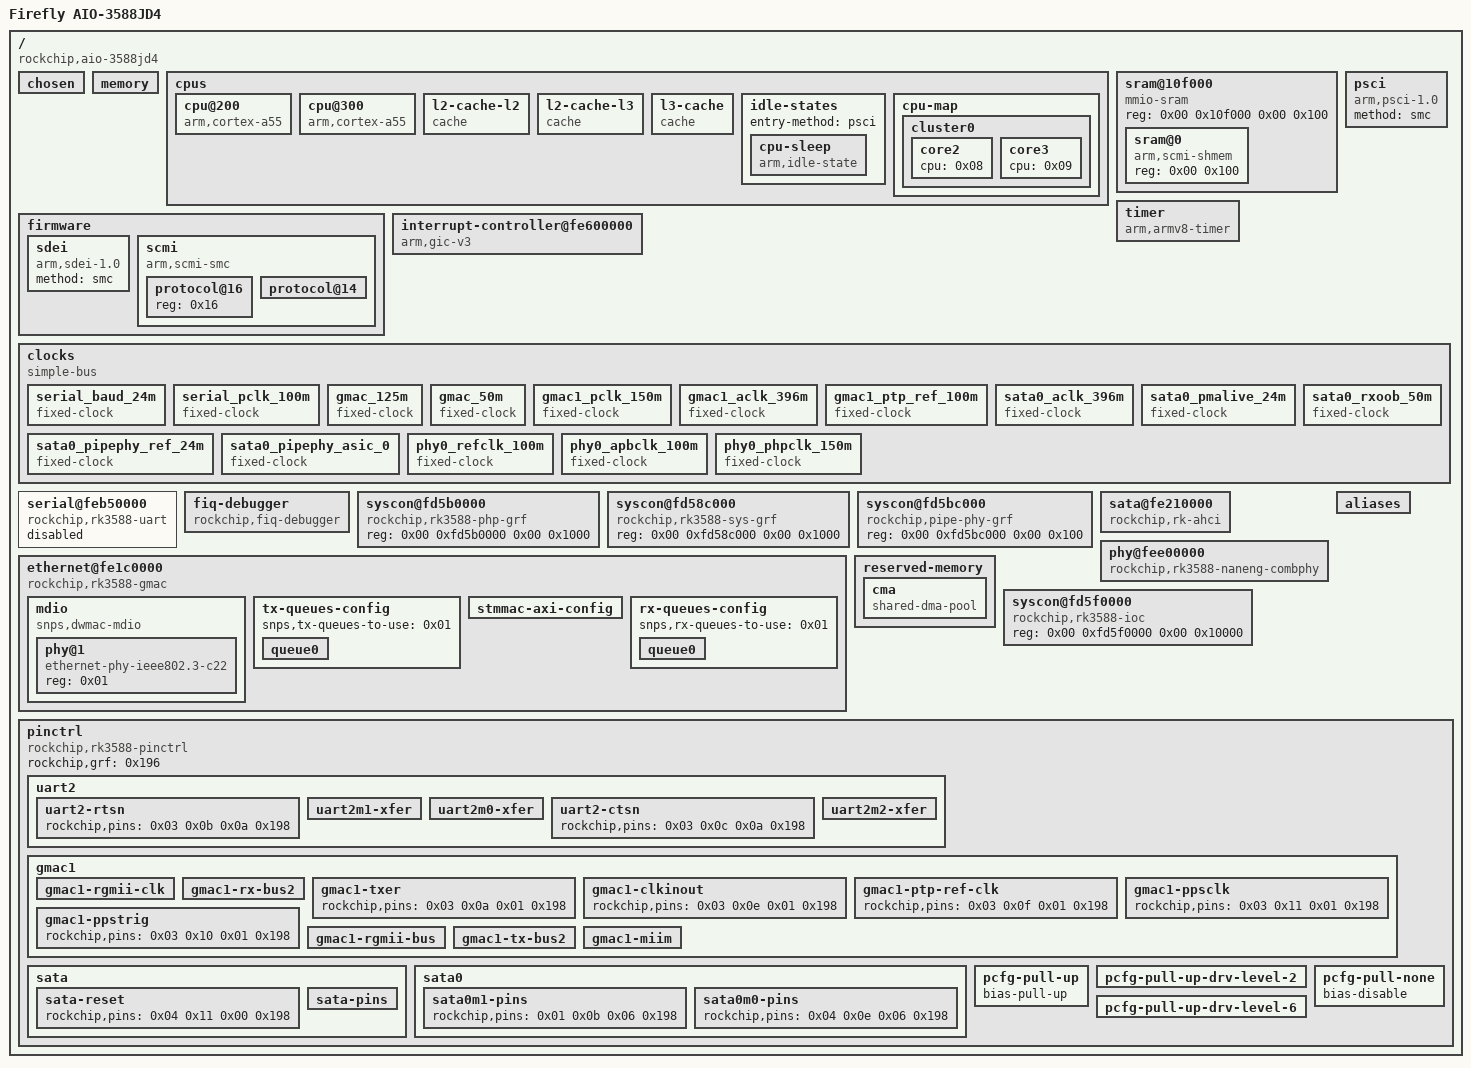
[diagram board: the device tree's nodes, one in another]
/dts-v1/;

/ {
	#address-cells = <0x02>;
	model = "Firefly AIO-3588JD4";
	serial-number = "a0deeea630de3975";
	#size-cells = <0x02>;
	interrupt-parent = <0x01>;
	compatible = "rockchip,aio-3588jd4\0rockchip,rk3588";

	chosen {
		linux,initrd-start = <0x01 0x0a200000>;
		linux,initrd-end = <0x01 0xaac8000>;
		bootargs = "rw earlycon=uart8250,mmio32,0xfeb50000 console=ttyFIQ0 irqchip.gicv3_pseudo_nmi=0 root=/dev/sda1";
		phandle = <0x48d>;
	};

	// DTB memory region: { address: 0xe000_0000, size: 0x1000_0000 } 256M
	// DTB memory region: { address: 0x1_0000_0000, size: 0xe000_0000 } 3.7G


	memory {
		device_type = "memory";
		reg = <0x00 0xe0000000 0x00 0x10000000 0x01 0x00000000 0x00 0xe0000000>;
	};

	cpus {
		#address-cells = <0x01>;
		#size-cells = <0x00>;

		cpu@200 {
			device_type = "cpu";
			compatible = "arm,cortex-a55";
			reg = <0x200>;
			enable-method = "psci";
			capacity-dmips-mhz = <0x212>;
			clocks = <0x0e 0x00>;
			operating-points-v2 = <0x0f>;
			cpu-idle-states = <0x10>;
			i-cache-size = <0x8000>;
			i-cache-line-size = <0x40>;
			i-cache-sets = <0x80>;
			d-cache-size = <0x8000>;
			d-cache-line-size = <0x40>;
			d-cache-sets = <0x80>;
			next-level-cache = <0x14>;
			phandle = <0x08>;
		};

		cpu@300 {
			device_type = "cpu";
			compatible = "arm,cortex-a55";
			reg = <0x300>;
			enable-method = "psci";
			capacity-dmips-mhz = <0x212>;
			clocks = <0x0e 0x00>;
			operating-points-v2 = <0x0f>;
			cpu-idle-states = <0x10>;
			i-cache-size = <0x8000>;
			i-cache-line-size = <0x40>;
			i-cache-sets = <0x80>;
			d-cache-size = <0x8000>;
			d-cache-line-size = <0x40>;
			d-cache-sets = <0x80>;
			next-level-cache = <0x15>;
			phandle = <0x09>;
		};

		l2-cache-l2 {
			compatible = "cache";
			cache-size = <0x20000>;
			cache-line-size = <0x40>;
			cache-sets = <0x200>;
			next-level-cache = <0x1e>;
			phandle = <0x14>;
		};

		l2-cache-l3 {
			compatible = "cache";
			cache-size = <0x20000>;
			cache-line-size = <0x40>;
			cache-sets = <0x200>;
			next-level-cache = <0x1e>;
			phandle = <0x15>;
		};

		l3-cache {
			compatible = "cache";
			cache-size = <0x300000>;
			cache-sets = <0x1000>;
			cache-line-size = <0x40>;
			phandle = <0x1e>;
		};

		idle-states {
			entry-method = "psci";

			cpu-sleep {
				compatible = "arm,idle-state";
				entry-latency-us = <0x64>;
				exit-latency-us = <0x78>;
				min-residency-us = <0x3e8>;
				local-timer-stop;
				arm,psci-suspend-param = <0x10000>;
				phandle = <0x10>;
			};
		};

		cpu-map {
			cluster0 {
				core2 {
					cpu = <0x08>;
				};

				core3 {
					cpu = <0x09>;
				};
			};
		};
	};

	sram@10f000 {
		#address-cells = <0x01>;
		#size-cells = <0x01>;
		compatible = "mmio-sram";
		ranges = <0x00 0x00 0x10f000 0x100>;
		reg = <0x00 0x10f000 0x00 0x100>;

		sram@0 {
			compatible = "arm,scmi-shmem";
			reg = <0x00 0x100>;
			phandle = <0x46>;
		};
	};

	firmware {
		sdei {
			method = "smc";
			compatible = "arm,sdei-1.0";
			phandle = <0x221>;
		};

		scmi {
			shmem = <0x46>;
			#address-cells = <0x01>;
			#size-cells = <0x00>;
			compatible = "arm,scmi-smc";
			phandle = <0x220>;
			arm,smc-id = <0x82000010>;

			protocol@16 {
				#reset-cells = <0x01>;
				reg = <0x16>;
				phandle = <0x11a>;
			};

			protocol@14 {
				assigned-clocks = <0x0e 0x00 0x0e 0x02 0x0e 0x03>;
				assigned-clock-rates = <0x30a32c00 0x30a32c00 0x30a32c00>;
				#clock-cells = <0x01>;
				reg = <0x14>;
				phandle = <0x0e>;
			};
		};
	};

	timer {
		interrupts = <0x01 0x0d 0xf04 0x01 0x0e 0xf04 0x01 0x0b 0xf04 0x01 0x0a 0xf04>;
		compatible = "arm,armv8-timer";
	};

	interrupt-controller@fe600000 {
		#address-cells = <0x02>;
		interrupts = <0x01 0x09 0x04>;
		#size-cells = <0x02>;
		compatible = "arm,gic-v3";
		ranges;
		#interrupt-cells = <0x03>;
		reg = <0x00 0xfe600000 0x00 0x10000 0x00 0xfe6c0000 0x00 0x100000>;
		phandle = <0x01>;
		interrupt-controller;

	};

	psci {
		method = "smc";
		compatible = "arm,psci-1.0";
	};

	// dummy clocks that are configured by VM1
	clocks {
		#address-cells = <0x02>;
		#size-cells = <0x02>;
		compatible = "simple-bus";
		ranges;

		// serial
		serial_baud_24m {
			clock-output-names = "serial_baud_24m";
			compatible = "fixed-clock";
			clock-frequency = <24000000>;
			#clock-cells = <0>;
			phandle = <0xbb>;
		};

		serial_pclk_100m {
			clock-output-names = "serial_pclk_100m";
			compatible = "fixed-clock";
			clock-frequency = <100000000>;
			#clock-cells = <0>;
			phandle = <0xac>;
		};

		// ethernet
		gmac_125m {
			clock-output-names = "gmac_125m";
			compatible = "fixed-clock";
			clock-frequency = <125000000>;
			#clock-cells = <0>;
			phandle = <0x144>;
		};

		gmac_50m {
			clock-output-names = "gmac_50m";
			compatible = "fixed-clock";
			clock-frequency = <50000000>;
			#clock-cells = <0>;
			phandle = <0x145>;
		};

		gmac1_pclk_150m {
			clock-output-names = "gmac1_pclk_150m";
			compatible = "fixed-clock";
			clock-frequency = <150000000>;
			#clock-cells = <0>;
			phandle = <0x168>;
		};

		gmac1_aclk_396m {
			clock-output-names = "gmac1_aclk_396m";
			compatible = "fixed-clock";
			clock-frequency = <396000000>;
			#clock-cells = <0>;
			phandle = <0x16d>;
		};

		gmac1_ptp_ref_100m {
			clock-output-names = "gmac1_ptp_ref_100m";
			compatible = "fixed-clock";
			clock-frequency = <100000000>;
			#clock-cells = <0>;
			phandle = <0x143>;
		};

		sata0_aclk_396m {
			clock-output-names = "sata0_aclk_396m";
			compatible = "fixed-clock";
			clock-frequency = <396000000>;
			#clock-cells = <0>;
			phandle = <0x171>;
		};

		sata0_pmalive_24m {
			clock-output-names = "sata0_pmalive_24m";
			compatible = "fixed-clock";
			clock-frequency = <24000000>;
			#clock-cells = <0>;
			phandle = <0x16e>;
		};

		sata0_rxoob_50m {
			clock-output-names = "sata0_rxoob_50m";
			compatible = "fixed-clock";
			clock-frequency = <50000000>;
			#clock-cells = <0>;
			phandle = <0x174>;
		};

		sata0_pipephy_ref_24m {
			clock-output-names = "sata0_pipephy_ref_24m";
			compatible = "fixed-clock";
			clock-frequency = <24000000>;
			#clock-cells = <0>;
			phandle = <0x163>;
		};

		sata0_pipephy_asic_0 {
			clock-output-names = "sata0_pipephy_asic_0";
			compatible = "fixed-clock";
			clock-frequency = <0>;
			#clock-cells = <0>;
			phandle = <0x17e>;
		};

		phy0_refclk_100m {
			clock-output-names = "phy0_refclk_100m";
			compatible = "fixed-clock";
			clock-frequency = <100000000>;
			#clock-cells = <0>;
			phandle = <0x2bd>;
		};

		phy0_apbclk_100m {
			clock-output-names = "phy0_apbclk_100m";
			compatible = "fixed-clock";
			clock-frequency = <100000000>;
			#clock-cells = <0>;
			phandle = <0x185>;
		};

		phy0_phpclk_150m {
			clock-output-names = "phy0_phpclk_150m";
			compatible = "fixed-clock";
			clock-frequency = <150000000>;
			#clock-cells = <0>;
			phandle = <0x166>;
		};
	};

	serial@feb50000 {
		reg-io-width = <0x04>;
		pinctrl-names = "default";
		pinctrl-0 = <0x161>;
		interrupts = <0x00 0x14d 0x04>;
		// Avoid driver messing with CRU
		clock-names = "baudclk\0apb_pclk";
		clocks = <0xbb 0xac>;
		compatible = "rockchip,rk3588-uart\0snps,dw-apb-uart";
		status = "disabled";
		reg = <0x00 0xfeb50000 0x00 0x100>;
		phandle = <0x2ca>;
		dmas = <0x7c 0x0a 0x7c 0x0b>;
		reg-shift = <0x02>;
	};

	fiq-debugger {
		pinctrl-names = "default";
		rockchip,irq-mode-enable = <0x01>;
		rockchip,baudrate = <0x1c200>;
		pinctrl-0 = <0x1ce>;
		interrupts = <0x00 0x1a7 0x08>;
		rockchip,wake-irq = <0x00>;
		compatible = "rockchip,fiq-debugger";
		status = "okay";
		phandle = <0x490>;
		rockchip,serial-id = <0x02>;
	};

	syscon@fd5b0000 {
		compatible = "rockchip,rk3588-php-grf\0syscon";
		reg = <0x00 0xfd5b0000 0x00 0x1000>;
		phandle = <0x76>;
	};

	syscon@fd58c000 {
		compatible = "rockchip,rk3588-sys-grf\0syscon\0simple-mfd";
		reg = <0x00 0xfd58c000 0x00 0x1000>;
		phandle = <0xc8>;
	};

	syscon@fd5bc000 {
		compatible = "rockchip,pipe-phy-grf\0syscon";
		reg = <0x00 0xfd5bc000 0x00 0x100>;
		phandle = <0x194>;
	};

	sata@fe210000 {
		phy-names = "sata-phy";
		clock-names = "sata\0pmalive\0rxoob\0ref\0asic";
		interrupts = <0x00 0x111 0x04>;
		clocks = <0x171 0x16e 0x174 0x163 0x17e>;
		compatible = "rockchip,rk-ahci\0snps,dwc-ahci";
		status = "okay";
		interrupt-names = "hostc";
		phys = <0x108 0x01>;
		reg = <0x00 0xfe210000 0x00 0x1000>;
		phandle = <0x290>;
		ports-implemented = <0x01>;
	};

	phy@fee00000 {
		rockchip,pipe-grf = <0x76>;
		clock-names = "refclk\0apbclk\0phpclk";
		clocks = <0x2bd 0x185 0x166>;
		#phy-cells = <0x01>;
		compatible = "rockchip,rk3588-naneng-combphy";
		status = "okay";
		rockchip,pipe-phy-grf = <0x194>;
		reg = <0x00 0xfee00000 0x00 0x100>;
		phandle = <0x108>;
		// resets = <0x02 0x20005 0x02 0x4d6>;
		// reset-names = "combphy-apb\0combphy";
	};

	ethernet@fe1c0000 {
		power-domains = <0x60 0x21>;
		pinctrl-names = "default";
		phy-mode = "rgmii-rxid";
		snps,mixed-burst;
		snps,mtl-rx-config = <0x10b>;
		pinctrl-0 = <0x10e 0x10f 0x110 0x111 0x112>;
		clock-names = "stmmaceth\0clk_mac_ref\0pclk_mac\0aclk_mac\0ptp_ref";
		snps,mtl-tx-config = <0x10c>;
		local-mac-address = [a6 50 47 45 20 ee];
		interrupt-names = "macirq\0eth_wake_irq";
		interrupts = <0x00 0xea 0x04 0x00 0xe9 0x04>;
		clocks = <0x144 0x145 0x168 0x16d 0x143>;
		clock_in_out = "output";
		snps,tso;
		compatible = "rockchip,rk3588-gmac\0snps,dwmac-4.20a";
		status = "okay";
		rockchip,grf = <0xc8>;
		// reset-names = "stmmaceth";
		// resets = <0x02 0x20b>;
		// snps,reset-active-low;
		// snps,reset-gpio = <0x10d 0x08 0x01>;
		// snps,reset-delays-us = <0x00 0x4e20 0x186a0>;
		reg = <0x00 0xfe1c0000 0x00 0x10000>;
		rockchip,php_grf = <0x76>;
		phandle = <0x109>;
		phy-handle = <0x113>;
		tx_delay = <0x40>;
		snps,axi-config = <0x10a>;

		mdio {
			#address-cells = <0x01>;
			#size-cells = <0x00>;
			compatible = "snps,dwmac-mdio";
			phandle = <0x28f>;

			phy@1 {
				compatible = "ethernet-phy-ieee802.3-c22";
				reg = <0x01>;
				phandle = <0x113>;
			};
		};

		tx-queues-config {
			phandle = <0x10c>;
			snps,tx-queues-to-use = <0x01>;

			queue0 {
			};
		};

		stmmac-axi-config {
			snps,wr_osr_lmt = <0x04>;
			phandle = <0x10a>;
			snps,blen = <0x00 0x00 0x00 0x00 0x10 0x08 0x04>;
			snps,rd_osr_lmt = <0x08>;
		};

		rx-queues-config {
			snps,rx-queues-to-use = <0x01>;
			phandle = <0x10b>;

			queue0 {
			};
		};
	};

	reserved-memory {
		#address-cells = <0x02>;
		#size-cells = <0x02>;
		ranges;

		cma {
			linux,cma-default;
			compatible = "shared-dma-pool";
			size = <0x00 0x800000>;
			reusable;
		};
	};

	aliases {
		serial2 = "/serial@feb50000";
		ethernet1 = "/ethernet@fe1c0000";
		mmc1 = "/mmc@fe2c0000";
	};

	__symbols__ {
		chosen = "/chosen";
		gic = "/interrupt-controller@fe600000";
		uart2 = "/serial@feb50000";

		scmi_shmem = "/sram@10f000/sram@0";
		scmi = "/firmware/scmi";
		scmi_reset = "/firmware/scmi/protocol@16";
		scmi_clk = "/firmware/scmi/protocol@14";

		gmac1 = "/ethernet@fe1c0000";
		mdio1 = "/ethernet@fe1c0000/mdio";
		rgmii_phy1 = "/ethernet@fe1c0000/mdio/phy@1";
		gmac1_mtl_rx_setup = "/ethernet@fe1c0000/rx-queues-config";
		gmac1_mtl_tx_setup = "/ethernet@fe1c0000/tx-queues-config";
		gmac1_stmmac_axi_setup = "/ethernet@fe1c0000/stmmac-axi-config";

		sata0 = "/sata@fe210000";
		sata0m0_pins = "/pinctrl/sata0/sata0m0-pins";
		sata0m1_pins = "/pinctrl/sata0/sata0m1-pins";

	};

	syscon@fd5f0000 {
		compatible = "rockchip,rk3588-ioc\0syscon";
		reg = <0x00 0xfd5f0000 0x00 0x10000>;
		phandle = <0x196>;
	};

	pinctrl {
		#address-cells = <0x02>;
		#size-cells = <0x02>;
		compatible = "rockchip,rk3588-pinctrl";
		ranges;
		rockchip,grf = <0x196>;
		phandle = <0x197>;

		uart2 {

			uart2-rtsn {
				rockchip,pins = <0x03 0x0b 0x0a 0x198>;
				phandle = <0x427>;
			};

			uart2m1-xfer {
				rockchip,pins = <0x04 0x19 0x0a 0x19e 0x04 0x18 0x0a 0x19e>;
				phandle = <0x161>;
			};

			uart2m0-xfer {
				rockchip,pins = <0x00 0x0e 0x0a 0x19e 0x00 0x0d 0x0a 0x19e>;
				phandle = <0x1ce>;
			};

			uart2-ctsn {
				rockchip,pins = <0x03 0x0c 0x0a 0x198>;
				phandle = <0x426>;
			};

			uart2m2-xfer {
				rockchip,pins = <0x03 0x0a 0x0a 0x19e 0x03 0x09 0x0a 0x19e>;
				phandle = <0x425>;
			};
		};

		gmac1 {

			gmac1-rgmii-clk {
				rockchip,pins = <0x03 0x05 0x01 0x198 0x03 0x04 0x01 0x198>;
				phandle = <0x111>;
			};

			gmac1-rx-bus2 {
				rockchip,pins = <0x03 0x07 0x01 0x198 0x03 0x08 0x01 0x198 0x03 0x09 0x01 0x198>;
				phandle = <0x110>;
			};

			gmac1-txer {
				rockchip,pins = <0x03 0x0a 0x01 0x198>;
				phandle = <0x332>;
			};

			gmac1-clkinout {
				rockchip,pins = <0x03 0x0e 0x01 0x198>;
				phandle = <0x32e>;
			};

			gmac1-ptp-ref-clk {
				rockchip,pins = <0x03 0x0f 0x01 0x198>;
				phandle = <0x331>;
			};

			gmac1-ppsclk {
				rockchip,pins = <0x03 0x11 0x01 0x198>;
				phandle = <0x32f>;
			};

			gmac1-ppstrig {
				rockchip,pins = <0x03 0x10 0x01 0x198>;
				phandle = <0x330>;
			};

			gmac1-rgmii-bus {
				rockchip,pins = <0x03 0x02 0x01 0x198 0x03 0x03 0x01 0x198 0x03 0x00 0x01 0x19a 0x03 0x01 0x01 0x19a>;
				phandle = <0x112>;
			};

			gmac1-tx-bus2 {
				rockchip,pins = <0x03 0x0b 0x01 0x19a 0x03 0x0c 0x01 0x19a 0x03 0x0d 0x01 0x198>;
				phandle = <0x10f>;
			};

			gmac1-miim {
				rockchip,pins = <0x03 0x12 0x01 0x198 0x03 0x13 0x01 0x198>;
				phandle = <0x10e>;
			};
		};

		sata {

			sata-reset {
				rockchip,pins = <0x04 0x11 0x00 0x198>;
				phandle = <0x3e7>;
			};

			sata-pins {
				rockchip,pins = <0x00 0x16 0x0d 0x198 0x00 0x1c 0x0d 0x198 0x00 0x1d 0x0d 0x198>;
				phandle = <0x3e6>;
			};
		};

		sata0 {

			sata0m1-pins {
				rockchip,pins = <0x01 0x0b 0x06 0x198>;
				phandle = <0x3e9>;
			};

			sata0m0-pins {
				rockchip,pins = <0x04 0x0e 0x06 0x198>;
				phandle = <0x3e8>;
			};
		};

		// output

		// pull up

		pcfg-pull-up {
			phandle = <0x19e>;
			bias-pull-up;
		};

		pcfg-pull-up-drv-level-2 {
			drive-strength = <0x02>;
			phandle = <0x199>;
			bias-pull-up;
		};

		pcfg-pull-up-drv-level-6 {
			drive-strength = <0x06>;
			phandle = <0x19a>;
			bias-pull-up;
		};

		// pull down

		// pull none

		pcfg-pull-none {
			bias-disable;
			phandle = <0x198>;
		};
	};

};
